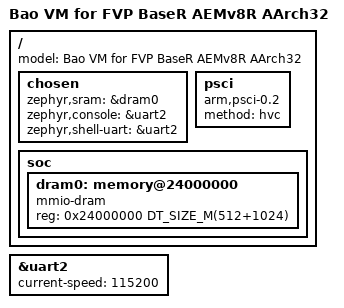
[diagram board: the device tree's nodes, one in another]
/*
 * Copyright (c) 2021 Arm Limited (or its affiliates). All rights reserved.
 * SPDX-License-Identifier: Apache-2.0
 */

/dts-v1/;

#include <arm64/fvp/fvp-aemv8r.dtsi>

/ {
	model = "Bao VM for FVP BaseR AEMv8R AArch32";

	chosen {
		/*
		 * The SRAM node is actually located in the
		 * DRAM region of the FVP BaseR AEMv8R.
		 */
		zephyr,sram = &dram0;
		zephyr,console = &uart2;
		zephyr,shell-uart = &uart2;
	};

	psci {
		compatible = "arm,psci-0.2";
		method = "hvc";
	};

	soc {
		dram0: memory@24000000 {
			compatible = "mmio-dram";
			reg = <0x24000000 DT_SIZE_M(512+1024)>;
		};
	};
};

&uart2 {
	status = "okay";
	current-speed = <115200>;
};
